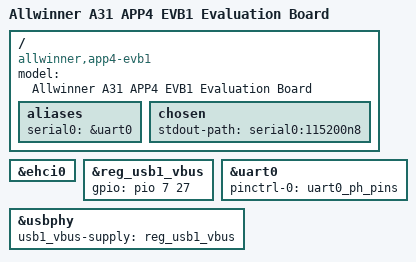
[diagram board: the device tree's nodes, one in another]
/dts-v1/;
#include "sun6i-a31.dtsi"
#include "sunxi-common-regulators.dtsi"
#include <dt-bindings/gpio/gpio.h>
/ {
	model = "Allwinner A31 APP4 EVB1 Evaluation Board";
	compatible = "allwinner,app4-evb1", "allwinner,sun6i-a31";
	aliases {
		serial0 = &uart0;
	};
	chosen {
		stdout-path = "serial0:115200n8";
	};
};
&ehci0 {
	status = "okay";
};
&reg_usb1_vbus {
	gpio = <&pio 7 27 GPIO_ACTIVE_HIGH>;
	status = "okay";
};
&uart0 {
	pinctrl-names = "default";
	pinctrl-0 = <&uart0_ph_pins>;
	status = "okay";
};
&usbphy {
	usb1_vbus-supply = <&reg_usb1_vbus>;
	status = "okay";
};
